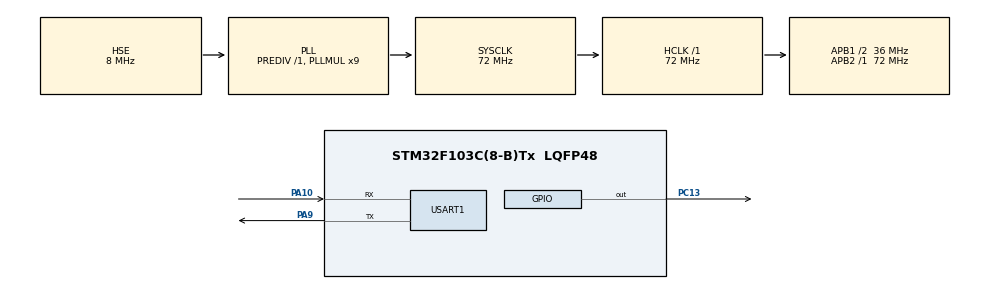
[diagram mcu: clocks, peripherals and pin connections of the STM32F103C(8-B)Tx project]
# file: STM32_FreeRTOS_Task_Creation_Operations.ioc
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FREERTOS.INCLUDE_vTaskDelayUntil=1
FREERTOS.Tasks01=defaultTask,0,128,StartDefaultTask,Default,NULL,Dynamic,NULL,NULL;Task2,0,128,Task2_Init,Default,NULL,Dynamic,NULL,NULL
FREERTOS.configUSE_NEWLIB_REENTRANT=1
Mcu.Family=STM32F1
Mcu.Name=STM32F103C(8-B)Tx
Mcu.Package=LQFP48
NVIC.PriorityGroup=NVIC_PRIORITYGROUP_4
NVIC.TIM2_IRQn=true\:15\:0\:false\:false\:true\:false\:false\:true\:true
NVIC.TimeBase=TIM2_IRQn
NVIC.TimeBaseIP=TIM2
NVIC.USART1_IRQn=true\:5\:0\:false\:false\:true\:true\:true\:true\:true
PA10.Mode=Asynchronous
PA10.Signal=USART1_RX
PA13.Mode=Serial_Wire
PA13.Signal=SYS_JTMS-SWDIO
PA14.Mode=Serial_Wire
PA14.Signal=SYS_JTCK-SWCLK
PA9.Mode=Asynchronous
PA9.Signal=USART1_TX
PC13-TAMPER-RTC.Signal=GPIO_Output
PD0-OSC_IN.Mode=HSE-External-Oscillator
PD0-OSC_IN.Signal=RCC_OSC_IN
PD1-OSC_OUT.Mode=HSE-External-Oscillator
PD1-OSC_OUT.Signal=RCC_OSC_OUT
ProjectManager.HeapSize=0x200
ProjectManager.StackSize=0x400
ProjectManager.TargetToolchain=STM32CubeIDE
RCC.AHBFreq_Value=72000000
RCC.APB1CLKDivider=RCC_HCLK_DIV2
RCC.APB1Freq_Value=36000000
RCC.APB1TimFreq_Value=72000000
RCC.APB2Freq_Value=72000000
RCC.APB2TimFreq_Value=72000000
RCC.HCLKFreq_Value=72000000
RCC.PLLMUL=RCC_PLL_MUL9
RCC.PLLSourceVirtual=RCC_PLLSOURCE_HSE
RCC.SYSCLKFreq_VALUE=72000000
RCC.SYSCLKSource=RCC_SYSCLKSOURCE_PLLCLK
RCC.USBFreq_Value=72000000
USART1.VirtualMode=VM_ASYNC
VP_FREERTOS_VS_CMSIS_V1.Mode=CMSIS_V1
VP_SYS_VS_tim2.Mode=TIM2
board=custom

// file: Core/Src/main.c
/* USER CODE BEGIN Header */
/**
 ******************************************************************************
 * @file           : main.c
 * @brief          : Simple CMSIS V1 RTOS example
 ******************************************************************************
 */
/* USER CODE END Header */
#include "main.h"
#include "cmsis_os.h"

/* USER CODE BEGIN Includes */
#include <string.h>
#include <stdio.h>
/* USER CODE END Includes */

UART_HandleTypeDef huart1;

osThreadId defaultTaskHandle;
osThreadId Task2Handle;
/* USER CODE BEGIN PV */
osThreadId Task3Handle;
/* USER CODE END PV */

void SystemClock_Config(void);
static void MX_GPIO_Init(void);
static void MX_USART1_UART_Init(void);
void StartDefaultTask(void const * argument);
void Task2_Init(void const * argument);

/* USER CODE BEGIN PFP */
void Task3_Init(void const *argument);
/* USER CODE END PFP */

int main(void)
{

  /* MCU Configuration--------------------------------------------------------*/

  /* Reset of all peripherals, Initializes the Flash interface and the Systick. */
  HAL_Init();

  /* Configure the system clock */
  SystemClock_Config();

  /* Initialize all configured peripherals */
  MX_GPIO_Init();
  MX_USART1_UART_Init();
  /* USER CODE BEGIN 2 */

  uint8_t data[] = "Free RTOS Test\n";
  HAL_UART_Transmit(&huart1, data, sizeof(data), 500);

  /* USER CODE END 2 */

  /* Create the thread(s) */
  /* definition and creation of defaultTask */
  osThreadDef(defaultTask, StartDefaultTask, osPriorityNormal, 0, 128);
  defaultTaskHandle = osThreadCreate(osThread(defaultTask), NULL);

  /* definition and creation of Task2 */
  osThreadDef(Task2, Task2_Init, osPriorityAboveNormal, 0, 128);
  Task2Handle = osThreadCreate(osThread(Task2), NULL);

  /* USER CODE BEGIN RTOS_THREADS */
  /* add threads, ... */
  osThreadDef(Task3, Task3_Init, osPriorityBelowNormal, 0, 128);
  Task3Handle = osThreadCreate(osThread(Task3), NULL);
  /* USER CODE END RTOS_THREADS */

  /* Start scheduler */
  osKernelStart();

  /* We should never get here as control is now taken by the scheduler */

  /* Infinite loop */
  while(1)
  {

  }
}

void SystemClock_Config(void)
{
  RCC_OscInitTypeDef RCC_OscInitStruct = {0};
  RCC_ClkInitTypeDef RCC_ClkInitStruct = {0};

  /** Initializes the RCC Oscillators according to the specified parameters
  * in the RCC_OscInitTypeDef structure.
  */
  RCC_OscInitStruct.OscillatorType = RCC_OSCILLATORTYPE_HSE;
  RCC_OscInitStruct.HSEState = RCC_HSE_ON;
  RCC_OscInitStruct.HSEPredivValue = RCC_HSE_PREDIV_DIV1;
  RCC_OscInitStruct.HSIState = RCC_HSI_ON;
  RCC_OscInitStruct.PLL.PLLState = RCC_PLL_ON;
  RCC_OscInitStruct.PLL.PLLSource = RCC_PLLSOURCE_HSE;
  RCC_OscInitStruct.PLL.PLLMUL = RCC_PLL_MUL9;
  if (HAL_RCC_OscConfig(&RCC_OscInitStruct) != HAL_OK)
  {
    Error_Handler();
  }

  /** Initializes the CPU, AHB and APB buses clocks
  */
  RCC_ClkInitStruct.ClockType = RCC_CLOCKTYPE_HCLK|RCC_CLOCKTYPE_SYSCLK
                              |RCC_CLOCKTYPE_PCLK1|RCC_CLOCKTYPE_PCLK2;
  RCC_ClkInitStruct.SYSCLKSource = RCC_SYSCLKSOURCE_PLLCLK;
  RCC_ClkInitStruct.AHBCLKDivider = RCC_SYSCLK_DIV1;
  RCC_ClkInitStruct.APB1CLKDivider = RCC_HCLK_DIV2;
  RCC_ClkInitStruct.APB2CLKDivider = RCC_HCLK_DIV1;

  if (HAL_RCC_ClockConfig(&RCC_ClkInitStruct, FLASH_LATENCY_2) != HAL_OK)
  {
    Error_Handler();
  }
}

static void MX_USART1_UART_Init(void)
{

  huart1.Instance = USART1;
  huart1.Init.BaudRate = 115200;
  huart1.Init.WordLength = UART_WORDLENGTH_8B;
  huart1.Init.StopBits = UART_STOPBITS_1;
  huart1.Init.Parity = UART_PARITY_NONE;
  huart1.Init.Mode = UART_MODE_TX_RX;
  huart1.Init.HwFlowCtl = UART_HWCONTROL_NONE;
  huart1.Init.OverSampling = UART_OVERSAMPLING_16;
  if (HAL_UART_Init(&huart1) != HAL_OK)
  {
    Error_Handler();
  }

}

static void MX_GPIO_Init(void)
{
  GPIO_InitTypeDef GPIO_InitStruct = {0};

  /* GPIO Ports Clock Enable */
  __HAL_RCC_GPIOC_CLK_ENABLE();
  __HAL_RCC_GPIOD_CLK_ENABLE();
  __HAL_RCC_GPIOA_CLK_ENABLE();

  /*Configure GPIO pin Output Level */
  HAL_GPIO_WritePin(GPIOC, GPIO_PIN_13, GPIO_PIN_RESET);

  /*Configure GPIO pin : PC13 */
  GPIO_InitStruct.Pin = GPIO_PIN_13;
  GPIO_InitStruct.Mode = GPIO_MODE_OUTPUT_PP;
  GPIO_InitStruct.Pull = GPIO_NOPULL;
  GPIO_InitStruct.Speed = GPIO_SPEED_FREQ_LOW;
  HAL_GPIO_Init(GPIOC, &GPIO_InitStruct);

}

/* USER CODE BEGIN 4 */
void Task3_Init(void const *argument)
{
  uint8_t index = 0;
  while(1)
  {
    uint8_t data[] = "Hello from Task 3\n";
    HAL_UART_Transmit(&huart1, data, sizeof(data), 500);
    index++;

    if(index == 3)
    {
      uint32_t PreviousWakeTime = osKernelSysTick();
      osDelayUntil(&PreviousWakeTime, 3000);
    }

    if(index == 7)
    {
      uint8_t data[] = "Terminating Task 2\n";
      HAL_UART_Transmit(&huart1, data, sizeof(data), 500);
      osThreadTerminate(Task2Handle);
    }
    osDelay(3000);
  }
}
/* USER CODE END 4 */

void StartDefaultTask(void const * argument)
{
  /* USER CODE BEGIN 5 */
  /* Infinite loop */
  for(;;)
  {
    uint8_t data[] = "Default Task\n";
    HAL_UART_Transmit(&huart1, data, sizeof(data), 500);
    osDelay(1000);
  }
  /* USER CODE END 5 */
}

void Task2_Init(void const * argument)
{
  /* USER CODE BEGIN Task2_Init */
  uint8_t index = 0;
  /* Infinite loop */
  for(;;)
  {
    char data[50];  // Change to char array
    sprintf(data, "Task 2 , index = %d\n", index++);
    HAL_UART_Transmit(&huart1, (uint8_t*) data, strlen(data), 500);

    if(index == 4)
    {
      uint8_t data[] = "Default Task Suspended\n";
      HAL_UART_Transmit(&huart1, data, sizeof(data), 500);
      osThreadSuspend(defaultTaskHandle);
    }

    if(index == 7)
    {
      uint8_t data[] = "Default Task Resumed\n";
      HAL_UART_Transmit(&huart1, data, sizeof(data), 500);
      osThreadSuspend(defaultTaskHandle);
    }
    osDelay(2000);
  }
  /* USER CODE END Task2_Init */
}

void HAL_TIM_PeriodElapsedCallback(TIM_HandleTypeDef *htim)
{
  if (htim->Instance == TIM2)
  {
    HAL_IncTick();
  }
}

void Error_Handler(void)
{
  __disable_irq();
}
